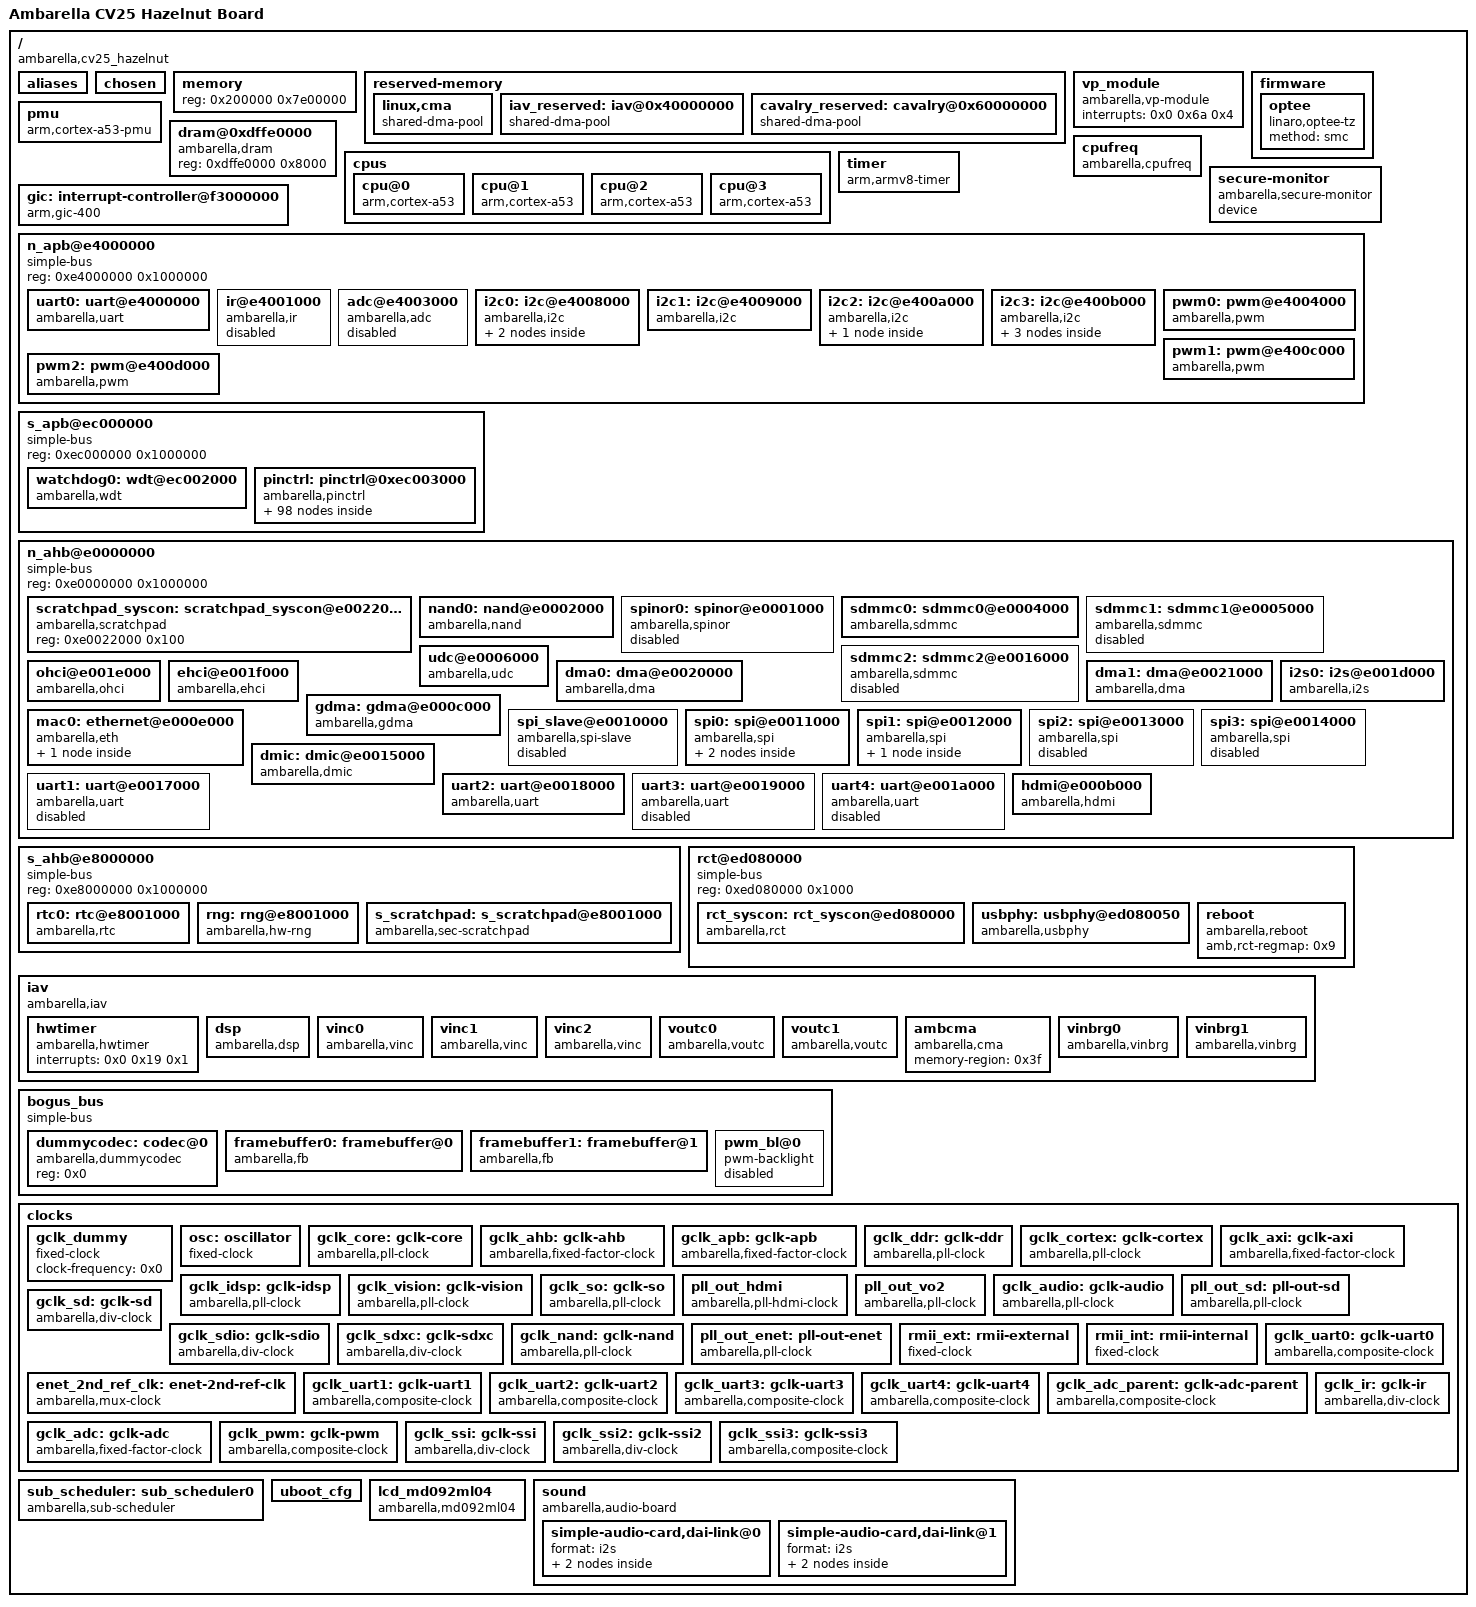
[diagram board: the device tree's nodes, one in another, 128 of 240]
/dts-v1/;

/ {
	compatible = "ambarella,cv25_hazelnut", "ambarella,cv25";
	interrupt-parent = <0x1>;
	#address-cells = <0x1>;
	#size-cells = <0x1>;
	model = "Ambarella CV25 Hazelnut Board";

	aliases {
		serial0 = "/n_apb@e4000000/uart@e4000000";
		serial1 = "/n_ahb@e0000000/uart@e0017000";
		serial2 = "/n_ahb@e0000000/uart@e0018000";
		serial3 = "/n_ahb@e0000000/uart@e0019000";
		serial4 = "/n_ahb@e0000000/uart@e001a000";
		nand = "/n_ahb@e0000000/nand@e0002000";
		sd0 = "/n_ahb@e0000000/sdmmc0@e0004000";
		sd1 = "/n_ahb@e0000000/sdmmc1@e0005000";
		sd2 = "/n_ahb@e0000000/sdmmc2@e0016000";
		spinor = "/n_ahb@e0000000/spinor@e0001000";
		i2c0 = "/n_apb@e4000000/i2c@e4008000";
		i2c1 = "/n_apb@e4000000/i2c@e4009000";
		i2c2 = "/n_apb@e4000000/i2c@e400a000";
		i2c3 = "/n_apb@e4000000/i2c@e400b000";
		spi0 = "/n_ahb@e0000000/spi@e0011000";
		spi1 = "/n_ahb@e0000000/spi@e0012000";
		spi2 = "/n_ahb@e0000000/spi@e0013000";
		spi3 = "/n_ahb@e0000000/spi@e0014000";
		ethernet0 = "/n_ahb@e0000000/ethernet@e000e000";
	};

	chosen {
		linux,stdout-path = "/n_apb@e4000000/uart@e4000000";
		stdout-path = "serial0";
		bootargs = "console=ttyS0 ubi.mtd=lnx root=ubi0:rootfs rw rootfstype=ubifs init=/linuxrc";
		ambarella,pm-gpio-notify-mcu = <0x6a>;
	};

	memory {
		device_type = "memory";
		reg = <0x200000 0x7e00000>;
	};

	reserved-memory {
		#address-cells = <0x1>;
		#size-cells = <0x1>;
		ranges;

		linux,cma {
			compatible = "shared-dma-pool";
			reusable;
			size = <0x3000000>;
			linux,cma-default;
		};

		iav_reserved: iav@0x40000000 {
			compatible = "shared-dma-pool";
			reusable;
			reg = <0x40000000 0x20000000>;
			linux,phandle = <0x3f>;
			phandle = <0x3f>;
		};

		cavalry_reserved: cavalry@0x60000000 {
			compatible = "shared-dma-pool";
			reusable;
			reg = <0x60000000 0x20000000>;
			linux,phandle = <0x4b>;
			phandle = <0x4b>;
		};
	};

	vp_module: vp_module {
		compatible = "ambarella,vp-module";
		interrupts = <0x0 0x6a 0x4>;
	};

	firmware {

		optee {
			compatible = "linaro,optee-tz";
			method = "smc";
		};
	};

	pmu {
		compatible = "arm,cortex-a53-pmu";
		interrupts = <0x0 0x4 0x4 0x0 0x5 0x4 0x0 0x6 0x4 0x0 0x7 0x4>;
	};

	dram@0xdffe0000 {
		compatible = "ambarella,dram";
		reg = <0xdffe0000 0x8000>;
	};

	cpus {
		#address-cells = <0x1>;
		#size-cells = <0x0>;

		cpu@0 {
			compatible = "arm,cortex-a53", "arm,armv8";
			device_type = "cpu";
			reg = <0x0>;
			enable-method = "spin-table";
		};

		cpu@1 {
			compatible = "arm,cortex-a53", "arm,armv8";
			device_type = "cpu";
			reg = <0x1>;
			enable-method = "spin-table";
		};

		cpu@2 {
			compatible = "arm,cortex-a53", "arm,armv8";
			device_type = "cpu";
			reg = <0x2>;
			enable-method = "spin-table";
		};

		cpu@3 {
			compatible = "arm,cortex-a53", "arm,armv8";
			device_type = "cpu";
			reg = <0x3>;
			enable-method = "spin-table";
		};
	};

	cpufreq {
		compatible = "ambarella,cpufreq";
		cpufreq-effective-clock = <0x0>;
		clocks = <0x2 0x3>;
		clock-names = "cortex_clk", "core_clk";
		clocks-frequency-cortex-core = <0x107ac0 0xa4100 0xc7380 0x7b0c0 0x927c0 0x52080>;
	};

	gic: interrupt-controller@f3000000 {
		compatible = "arm,gic-400";
		#interrupt-cells = <0x3>;
		#address-cells = <0x0>;
		interrupt-controller;
		reg = <0xf3001000 0x1000 0xf3002000 0x2000 0xf3004000 0x2000 0xf3006000 0x2000>;
		interrupts = <0x1 0x9 0xf04>;
		linux,phandle = <0x1>;
		phandle = <0x1>;
	};

	timer {
		compatible = "arm,armv8-timer";
		interrupts = <0x1 0xd 0xf08 0x1 0xe 0xf08 0x1 0xb 0xf08 0x1 0xa 0xf08>;
	};

	secure-monitor {
		compatible = "ambarella,secure-monitor";
		#address-cells = <0x1>;
		#size-cells = <0x0>;
		device;
	};

	n_apb@e4000000 {
		compatible = "simple-bus";
		#address-cells = <0x1>;
		#size-cells = <0x1>;
		reg = <0xe4000000 0x1000000>;
		ranges;

		uart0: uart@e4000000 {
			compatible = "ambarella,uart";
			reg = <0xe4000000 0x1000>;
			interrupts = <0x0 0x15 0x4>;
			pinctrl-names = "default";
			pinctrl-0 = <0x4>;
			clocks = <0x5>;
			status = "ok";
		};

		ir@e4001000 {
			compatible = "ambarella,ir";
			reg = <0xe4001000 0x1000>;
			interrupts = <0x0 0x14 0x4>;
			pinctrl-names = "default";
			pinctrl-0 = <0x6>;
			clocks = <0x7>;
			status = "disabled";
		};

		adc@e4003000 {
			compatible = "ambarella,adc";
			#io-channel-cells = <0x1>;
			reg = <0xe4003000 0x1000>;
			interrupts = <0x0 0xd 0x4>;
			clock-frequency = <0x2dc6c0>;
			clocks = <0x8>;
			amb,rct-regmap = <0x9>;
			amb,scaler-1v8 = <0x1>;
			status = "disabled";
		};

		i2c0: i2c@e4008000 {
			compatible = "ambarella,i2c";
			#address-cells = <0x1>;
			#size-cells = <0x0>;
			reg = <0xe4008000 0x1000>;
			interrupts = <0x0 0xf 0x4>;
			pinctrl-names = "default";
			pinctrl-0 = <0xa>;
			clocks = <0xb>;
			clock-frequency = <0x186a0>;
			amb,i2c-class = <0x81>;
			status = "ok";

			ak4951: codec@12 {
				compatible = "ambarella,ak4951";
				#sound-dai-cells = <0x0>;
				reg = <0x12>;
				gpios = <0xc 0xd 0x0>;
				pwr-gpios = <0xc 0xe 0x1>;
				linux,phandle = <0x4d>;
				phandle = <0x4d>;
			};

			ambvin0@01 {
				compatible = "ambarella,ambvin";
				reg = <0x1>;
			};
		};

		i2c1: i2c@e4009000 {
			compatible = "ambarella,i2c";
			#address-cells = <0x1>;
			#size-cells = <0x0>;
			reg = <0xe4009000 0x1000>;
			interrupts = <0x0 0x10 0x4>;
			pinctrl-names = "default";
			pinctrl-0 = <0xd>;
			clocks = <0xb>;
			clock-frequency = <0x186a0>;
			amb,i2c-class = <0x8>;
			status = "ok";
		};

		i2c2: i2c@e400a000 {
			compatible = "ambarella,i2c";
			#address-cells = <0x1>;
			#size-cells = <0x0>;
			reg = <0xe400a000 0x1000>;
			interrupts = <0x0 0x11 0x4>;
			clocks = <0xb>;
			pinctrl-names = "default";
			pinctrl-0 = <0xe>;
			clock-frequency = <0x186a0>;
			amb,i2c-class = <0x81>;
			status = "ok";

			it66121@4c {
				compatible = "it66121";
				reg = <0x4c>;
				rst_gpios = <0xc 0x3 0x0>;
			};
		};

		i2c3: i2c@e400b000 {
			compatible = "ambarella,i2c";
			#address-cells = <0x1>;
			#size-cells = <0x0>;
			reg = <0xe400b000 0x1000>;
			interrupts = <0x0 0x12 0x4>;
			clocks = <0xb>;
			pinctrl-names = "default";
			pinctrl-0 = <0xf>;
			clock-frequency = <0x186a0>;
			amb,i2c-class = <0x81>;
			status = "ok";

			pca9539: pca9539@74 {
				compatible = "nxp,pca9539";
				reg = <0x74>;
				gpio-controller;
				interrupt-parent = <0x10>;
				interrupt-controller;
				#gpio-cells = <0x2>;
				interrupts = <0x9 0x0>;
				linux,phandle = <0xc>;
				phandle = <0xc>;
			};

			isl12022: rtc@6f {
				compatible = "isil,isl12022";
				reg = <0x6f>;
			};

			ambvin1@01 {
				compatible = "ambarella,ambvin";
				reg = <0x1>;
			};
		};

		pwm0: pwm@e4004000 {
			compatible = "ambarella,pwm";
			reg = <0xe4004000 0x1000>;
			clock-frequency = <0x1e8480>;
			clocks = <0x11>;
			#pwm-cells = <0x3>;
			linux,phandle = <0x40>;
			phandle = <0x40>;
		};

		pwm1: pwm@e400c000 {
			compatible = "ambarella,pwm";
			reg = <0xe400c000 0x1000>;
			clock-frequency = <0x1e8480>;
			clocks = <0x11>;
			#pwm-cells = <0x3>;
		};

		pwm2: pwm@e400d000 {
			compatible = "ambarella,pwm";
			reg = <0xe400d000 0x1000>;
			clock-frequency = <0x989680>;
			clocks = <0x11>;
			#pwm-cells = <0x3>;
		};
	};

	s_apb@ec000000 {
		compatible = "simple-bus";
		#address-cells = <0x1>;
		#size-cells = <0x1>;
		reg = <0xec000000 0x1000000>;
		ranges;

		watchdog0: wdt@ec002000 {
			compatible = "ambarella,wdt";
			reg = <0xec002000 0x1000>;
			amb,rct-regmap = <0x9>;
			timeout-sec = <0xf>;
			amb,secure-ctrl-bit = <0x31>;
		};

		pinctrl: pinctrl@0xec003000 {
			compatible = "ambarella,pinctrl", "simple-bus";
			#address-cells = <0x1>;
			#size-cells = <0x0>;
			reg = <0xec003000 0x1000 0xec004000 0x1000 0xec005000 0x1000 0xec006000 0x1000 0xec000000 0x1000 0xe0022014 0x3c 0xed080314 0x13c>;
			reg-names = "gpio0", "gpio1", "gpio2", "gpio3", "iomux", "pad", "ds";
			#gpio-range-cells = <0x3>;
			linux,phandle = <0x12>;
			phandle = <0x12>;

			gpio: gpio@0 {
				compatible = "ambarella,gpio";
				reg = <0x0>;
				interrupts = <0x0 0x2b 0x4 0x0 0x2c 0x4 0x0 0x2d 0x4 0x0 0x2e 0x4>;
				gpio-controller;
				#gpio-cells = <0x2>;
				gpio-ranges = <0x12 0x0 0x0 0x6c>;
				interrupt-controller;
				#interrupt-cells = <0x2>;
				linux,phandle = <0x10>;
				phandle = <0x10>;
			};

			uart0_pins: uart0@0 {
				reg = <0x0>;
				amb,pinmux-ids = <0x1011 0x1012>;
				u-boot,dm-pre-reloc;
				linux,phandle = <0x4>;
				phandle = <0x4>;
			};

			uart1_pins: uart1@0 {
				reg = <0x0>;
				amb,pinmux-ids = <0x1057 0x1058>;
				linux,phandle = <0x31>;
				phandle = <0x31>;
			};

			uart1_flow_pins: uart1_flow@0 {
				reg = <0x0>;
				amb,pinmux-ids = <0x1059 0x105a>;
				linux,phandle = <0x32>;
				phandle = <0x32>;
			};

			uart2_pins: uart2@0 {
				reg = <0x0>;
				amb,pinmux-ids = <0x105b 0x105c>;
				linux,phandle = <0x34>;
				phandle = <0x34>;
			};

			uart2_flow_pins: uart2_flow@0 {
				reg = <0x0>;
				amb,pinmux-ids = <0x105d 0x105e>;
				linux,phandle = <0x35>;
				phandle = <0x35>;
			};

			uart3_pins_a: uart3@0 {
				reg = <0x0>;
				amb,pinmux-ids = <0x1048 0x1049>;
			};

			uart3_pins_b: uart3@1 {
				reg = <0x1>;
				amb,pinmux-ids = <0x4061 0x4062>;
				linux,phandle = <0x37>;
				phandle = <0x37>;
			};

			uart3_flow_pins_a: uart3_flow@0 {
				reg = <0x0>;
				amb,pinmux-ids = <0x104a 0x104b>;
			};

			uart3_flow_pins_b: uart3_flow@1 {
				reg = <0x1>;
				amb,pinmux-ids = <0x4063 0x4064>;
				linux,phandle = <0x38>;
				phandle = <0x38>;
			};

			uart4_pins_a: uart4@0 {
				reg = <0x0>;
				amb,pinmux-ids = <0x104c 0x104d>;
				linux,phandle = <0x3a>;
				phandle = <0x3a>;
			};

			uart4_pins_b: uart4@1 {
				reg = <0x1>;
				amb,pinmux-ids = <0x4065 0x4066>;
			};

			uart4_flow_pins_a: uart4_flow@0 {
				reg = <0x0>;
				amb,pinmux-ids = <0x104e 0x104f>;
				linux,phandle = <0x3b>;
				phandle = <0x3b>;
			};

			uart4_flow_pins_b: uart4_flow@1 {
				reg = <0x1>;
				amb,pinmux-ids = <0x4067 0x4068>;
			};

			nand0_pins: nand0@0 {
				reg = <0x0>;
				amb,pinmux-ids = <0x202d 0x202e 0x202f 0x2034 0x2035 0x2036 0x2037 0x2038 0x2039 0x203a 0x203b 0x203c 0x203d 0x203e 0x203f>;
				linux,phandle = <0x13>;
				phandle = <0x13>;
			};

			snand0_pins: snand0@0 {
				reg = <0x0>;
				amb,pinmux-ids = <0x402d 0x4037 0x403b 0x403c 0x403d 0x403e>;
				linux,phandle = <0x14>;
				phandle = <0x14>;
			};

			spinor0_pins: spinor0@0 {
				reg = <0x0>;
				amb,pinmux-ids = <0x302d 0x302f 0x3034 0x3035 0x3036 0x3037 0x3038 0x3039 0x303a 0x303b 0x303c 0x303d 0x303e>;
				linux,phandle = <0x16>;
				phandle = <0x16>;
			};

			sdmmc0_cd_pin: sdmmc0_cd@0 {
				reg = <0x0>;
				amb,pinmux-ids = <0x2032>;
				linux,phandle = <0x1a>;
				phandle = <0x1a>;
			};

			sdmmc0_wp_pin: sdmmc0_wp@0 {
				reg = <0x0>;
				amb,pinmux-ids = <0x2033>;
				linux,phandle = <0x1b>;
				phandle = <0x1b>;
			};

			sdmmc0_reset_pin: sdmmc0_reset@0 {
				reg = <0x0>;
				amb,pinmux-ids = <0x2051>;
			};

			sdmmc0_pins_1bit: sdmmc0@0 {
				reg = <0x0>;
				amb,pinmux-ids = <0x2030 0x2031 0x2040>;
			};

			sdmmc0_pins_4bit: sdmmc0@1 {
				reg = <0x1>;
				amb,pinmux-ids = <0x2030 0x2031 0x2040 0x2041 0x2042 0x2043>;
			};

			sdmmc0_pins_8bit: sdmmc0@2 {
				reg = <0x2>;
				amb,pinmux-ids = <0x2030 0x2031 0x2040 0x2041 0x2042 0x2043 0x2044 0x2045 0x2046 0x2047>;
				linux,phandle = <0x19>;
				phandle = <0x19>;
			};

			sdmmc1_cd_pin: sdmmc1_cd@0 {
				reg = <0x0>;
				amb,pinmux-ids = <0x204e>;
				linux,phandle = <0x1e>;
				phandle = <0x1e>;
			};

			sdmmc1_wp_pin: sdmmc1_wp@0 {
				reg = <0x0>;
				amb,pinmux-ids = <0x204f>;
				linux,phandle = <0x1f>;
				phandle = <0x1f>;
			};

			sdmmc1_reset_pin: sdmmc1_reset@0 {
				reg = <0x0>;
				amb,pinmux-ids = <0x2050>;
			};

			sdmmc1_pins_1bit: sdmmc1@0 {
				reg = <0x0>;
				amb,pinmux-ids = <0x2048 0x2049 0x204a>;
			};

			sdmmc1_pins_4bit: sdmmc1@1 {
				reg = <0x1>;
				amb,pinmux-ids = <0x2048 0x2049 0x204a 0x204b 0x204c 0x204d>;
				linux,phandle = <0x1d>;
				phandle = <0x1d>;
			};

			sdmmc2_cd_pin: sdmmc2_cd@0 {
				reg = <0x0>;
				amb,pinmux-ids = <0x1067>;
				linux,phandle = <0x22>;
				phandle = <0x22>;
			};

			sdmmc2_wp_pin: sdmmc2_wp@0 {
				reg = <0x0>;
				amb,pinmux-ids = <0x1068>;
			};

			sdmmc2_pins_1bit: sdmmc2@0 {
				reg = <0x0>;
				amb,pinmux-ids = <0x1065 0x1066 0x1061>;
			};

			sdmmc2_pins_4bit: sdmmc2@1 {
				reg = <0x1>;
				amb,pinmux-ids = <0x1065 0x1066 0x1061 0x1062 0x1063 0x1064>;
				linux,phandle = <0x21>;
				phandle = <0x21>;
			};

			rgmii_pins: eth0@0 {
				reg = <0x0>;
				amb,pinmux-ids = <0x401c 0x401d 0x401e 0x401f 0x4020 0x4021 0x4022 0x4023 0x4024 0x4025 0x4029 0x402a 0x402b 0x5026 0x5027>;
				linux,phandle = <0x28>;
				phandle = <0x28>;
			};

			rmii_pins: eth0@1 {
				reg = <0x1>;
				amb,pinmux-ids = <0x301c 0x301d 0x301e 0x3021 0x3022 0x3025 0x3029 0x302b 0x5026 0x5027>;
			};

			enet_ptp_pps_o_pins_a: enet_ptp_pps_o@0 {
				reg = <0x0>;
				amb,pinmux-ids = <0x4028>;
			};

			enet_ptp_pps_o_pins_b: enet_ptp_pps_o@1 {
				reg = <0x1>;
				amb,pinmux-ids = <0x3028>;
			};

			enet_2nd_ref_clk_pins_a: enet_2nd_ref_clk@0 {
				reg = <0x0>;
				amb,pinmux-ids = <0x302c>;
				linux,phandle = <0x29>;
				phandle = <0x29>;
			};

			enet_2nd_ref_clk_pins_b: enet_2nd_ref_clk@1 {
				reg = <0x1>;
				amb,pinmux-ids = <0x302a>;
			};

			i2c0_pins_a: i2c0@0 {
				reg = <0x0>;
				amb,pinmux-ids = <0x3001 0x3002>;
				linux,phandle = <0xa>;
				phandle = <0xa>;
			};

			i2c0_pins_b: i2c0@1 {
				reg = <0x1>;
				amb,pinmux-ids = <0x300f 0x3010>;
			};

			i2c0_pins_c: i2c0@2 {
				reg = <0x2>;
				amb,pinmux-ids = <0x304f 0x3050>;
			};

			i2c0_pins_d: i2c0@3 {
				reg = <0x3>;
				amb,pinmux-ids = <0x205f 0x2060>;
			};

			i2c1_pins_a: i2c1@0 {
				reg = <0x0>;
				amb,pinmux-ids = <0x2006 0x2007>;
			};

			i2c1_pins_b: i2c1@1 {
				reg = <0x1>;
				amb,pinmux-ids = <0x3065 0x3066>;
				linux,phandle = <0xd>;
				phandle = <0xd>;
			};

			i2c2_pins_a: i2c2@0 {
				reg = <0x0>;
				amb,pinmux-ids = <0x2004 0x2008>;
			};

			i2c2_pins_b: i2c2@1 {
				reg = <0x1>;
				amb,pinmux-ids = <0x3067 0x3068>;
				linux,phandle = <0xe>;
				phandle = <0xe>;
			};

			i2c3_pins: i2c3@0 {
				reg = <0x0>;
				amb,pinmux-ids = <0x200b 0x200c>;
				linux,phandle = <0xf>;
				phandle = <0xf>;
			};

			ir_pins: ir0@0 {
				reg = <0x0>;
				amb,pinmux-ids = <0x1003>;
				linux,phandle = <0x6>;
				phandle = <0x6>;
			};

			wdt_pins_a: wdt0@0 {
				reg = <0x0>;
				amb,pinmux-ids = <0x2003>;
			};

			wdt_pins_b: wdt0@1 {
				reg = <0x1>;
				amb,pinmux-ids = <0x3008>;
			};

			wdt_pins_c: wdt0@2 {
				reg = <0x2>;
				amb,pinmux-ids = <0x2015>;
			};

			wdt_pins_d: wdt0@3 {
				reg = <0x3>;
				amb,pinmux-ids = <0x202c>;
			};

			wdt_pins_e: wdt0@4 {
				reg = <0x4>;
				amb,pinmux-ids = <0x2054>;
			};

			wdt_pins_f: wdt0@5 {
				reg = <0x5>;
				amb,pinmux-ids = <0x5066>;
			};

			i2s0_pins: i2s0@0 {
				reg = <0x0>;
				amb,pinmux-ids = <0x1016 0x1017 0x1018 0x101b>;
				linux,phandle = <0x26>;
				phandle = <0x26>;
			};

			i2s0_ch2_pins: i2s0_ch2@0 {
				reg = <0x0>;
				amb,pinmux-ids = <0x1019 0x101a>;
			};

			dmic0_pins: dmic_pins@0 {
				reg = <0x0>;
				amb,pinmux-ids = <0x3014 0x3015>;
			};

			dmic1_pins: dmic_pins@1 {
				reg = <0x1>;
				amb,pinmux-ids = <0x3016 0x3017>;
			};

			dmic2_pins: dmic_pins@2 {
				reg = <0x2>;
				amb,pinmux-ids = <0x4019 0x401a>;
			};

			usb_host0_pins_a: uhc0@0 {
				reg = <0x0>;
				amb,pinmux-ids = <0x3019 0x301a>;
				linux,phandle = <0x3d>;
				phandle = <0x3d>;
			};

			usb_host0_pins_b: uhc0@1 {
				reg = <0x1>;
				amb,pinmux-ids = <0x4011 0x4012>;
			};

			usb_host0_pins_c: uhc0@2 {
				reg = <0x2>;
				amb,pinmux-ids = <0x3057 0x3059>;
			};

			usb_host0_pins_d: uhc0@3 {
				reg = <0x3>;
				amb,pinmux-ids = <0x5061 0x5062>;
			};

			pwm0_pins_a: pwm0@0 {
				reg = <0x0>;
				amb,pinmux-ids = <0x1013>;
			};

			pwm0_pins_b: pwm0@1 {
				reg = <0x1>;
				amb,pinmux-ids = <0x2020>;
			};

			pwm0_pins_c: pwm0@2 {
				reg = <0x2>;
				amb,pinmux-ids = <0x102c>;
				linux,phandle = <0x41>;
				phandle = <0x41>;
			};

			pwm1_pins: pwm1@0 {
				reg = <0x0>;
				amb,pinmux-ids = <0x1014>;
			};

			pwm2_pins: pwm2@0 {
				reg = <0x0>;
				amb,pinmux-ids = <0x1015>;
			};

			pwm3_pins_a: pwm3@0 {
				reg = <0x0>;
				amb,pinmux-ids = <0x3004>;
			};

			pwm3_pins_b: pwm3@1 {
				reg = <0x1>;
				amb,pinmux-ids = <0x2024>;
			};

			pwm4_pins_a: pwm4@0 {
				reg = <0x0>;
				amb,pinmux-ids = <0x3005>;
			};

			pwm4_pins_b: pwm4@1 {
				reg = <0x1>;
				amb,pinmux-ids = <0x2025>;
			};

			pwm5_pins_a: pwm5@0 {
				reg = <0x0>;
				amb,pinmux-ids = <0x3006>;
			};

			pwm5_pins_b: pwm5@1 {
				reg = <0x1>;
				amb,pinmux-ids = <0x2026>;
			};

			pwm6_pins_a: pwm6@0 {
				reg = <0x0>;
				amb,pinmux-ids = <0x3007>;
			};

			pwm6_pins_b: pwm6@1 {
				reg = <0x1>;
				amb,pinmux-ids = <0x2027>;
			};

			pwm7_pins_a: pwm7@0 {
				reg = <0x0>;
				amb,pinmux-ids = <0x3000>;
			};

			pwm7_pins_b: pwm7@1 {
				reg = <0x1>;
				amb,pinmux-ids = <0x2028>;
			};

			pwm7_pins_c: pwm7@2 {
				reg = <0x2>;
				amb,pinmux-ids = <0x5063>;
			};

			pwm8_pins_a: pwm8@0 {
				reg = <0x0>;
				amb,pinmux-ids = <0x201c>;
			};

			pwm8_pins_b: pwm8@1 {
				reg = <0x1>;
				amb,pinmux-ids = <0x2029>;
			};

			pwm8_pins_c: pwm8@2 {
				reg = <0x2>;
				amb,pinmux-ids = <0x5064>;
			};

			pwm9_pins_a: pwm9@0 {
				reg = <0x0>;
				amb,pinmux-ids = <0x201d>;
			};

			pwm9_pins_b: pwm9@1 {
				reg = <0x1>;
				amb,pinmux-ids = <0x202a>;
			};

			pwm9_pins_c: pwm9@2 {
				reg = <0x2>;
				amb,pinmux-ids = <0x5065>;
			};

			pwm10_pins: pwm10@0 {
				reg = <0x0>;
				amb,pinmux-ids = <0x201e>;
			};

			pwm11_pins: pwm11@0 {
				reg = <0x0>;
				amb,pinmux-ids = <0x201f>;
			};

			spi_slave_pins_a: spi_slave@0 {
				reg = <0x0>;
				amb,pinmux-ids = <0x200d 0x200e 0x200f 0x2010>;
				linux,phandle = <0x2b>;
				phandle = <0x2b>;
			};

			spi_slave_pins_b: spi_slave@1 {
				reg = <0x1>;
				amb,pinmux-ids = <0x3061 0x3062 0x3063 0x3064>;
			};

			spi0_pins_a: spi0@0 {
				reg = <0x0>;
				amb,pinmux-ids = <0x1004 0x1005 0x1006>;
				linux,phandle = <0x2c>;
				phandle = <0x2c>;
			};

			spi0_pins_b: spi0@1 {
				reg = <0x1>;
				amb,pinmux-ids = <0x2061 0x2062 0x2063>;
			};

			spi1_pins_a: spi1@0 {
				reg = <0x0>;
				amb,pinmux-ids = <0x2016 0x2017 0x2018>;
			};

			spi1_pins_b: spi1@1 {
				reg = <0x1>;
				amb,pinmux-ids = <0x3048 0x3049 0x304a>;
				linux,phandle = <0x2d>;
				phandle = <0x2d>;
			};

			spi1_pins_c: spi1@2 {
				reg = <0x2>;
				amb,pinmux-ids = <0x2057 0x2058 0x2059>;
			};

			spi1_pins_d: spi1@3 {
				reg = <0x3>;
				amb,pinmux-ids = <0x2065 0x2066 0x2067>;
			};

			spi2_pins: spi2@0 {
				reg = <0x0>;
				amb,pinmux-ids = <0x1009 0x100a 0x100b>;
				linux,phandle = <0x2e>;
				phandle = <0x2e>;
			};

			spi3_pins: spi3@0 {
				reg = <0x0>;
				amb,pinmux-ids = <0x100d 0x100e 0x100f>;
				linux,phandle = <0x30>;
				phandle = <0x30>;
			};

			vout0_pins: vout0@0 {
				reg = <0x0>;
				amb,pinmux-ids = <0x101c 0x101d 0x101e 0x101f 0x1020 0x1021 0x1022 0x1023 0x1024 0x1025 0x1026 0x1027 0x1028 0x1029 0x102a 0x102b 0x305b 0x305c 0x305d 0x305e>;
				amb,pinconf-ids = <0xba001c 0xba001d 0xba001e 0xba001f 0xba0020 0xba0021 0xba0022 0xba0023 0xba0024 0xba0025 0xba0026 0xba0027 0xba0028 0xba0029 0xba002a 0xba002b 0xba005b 0xba005c 0xba005d 0xba005e>;
			};
		};
	};

	n_ahb@e0000000 {
		compatible = "simple-bus";
		#address-cells = <0x1>;
		#size-cells = <0x1>;
		reg = <0xe0000000 0x1000000>;
		ranges;

		scratchpad_syscon: scratchpad_syscon@e0022000 {
			compatible = "ambarella,scratchpad", "syscon";
			reg = <0xe0022000 0x100>;
			linux,phandle = <0x24>;
			phandle = <0x24>;
		};

		nand0: nand@e0002000 {
			compatible = "ambarella,nand";
			#address-cells = <0x1>;
			#size-cells = <0x1>;
			reg = <0xe0002000 0x1000>;
			interrupts = <0x0 0x44 0x4>;
			amb,rct-regmap = <0x9>;
			pinctrl-names = "default", "spinand";
			pinctrl-0 = <0x13>;
			pinctrl-1 = <0x14>;
			clocks = <0x15>;
			nand-on-flash-bbt;
		};

		spinor0: spinor@e0001000 {
			compatible = "ambarella,spinor";
			reg = <0xe0001000 0x2ff>;
			interrupts = <0x0 0x49 0x4>;
			pinctrl-names = "default";
			pinctrl-0 = <0x16>;
			clocks = <0x17>;
			dmas = <0x18 0x5 0x18 0x6>;
			dma-names = "tx", "rx";
			max-frequency = <0x2faf080>;
			status = "disabled";
		};

		sdmmc0: sdmmc0@e0004000 {
			compatible = "ambarella,sdmmc";
			#address-cells = <0x1>;
			#size-cells = <0x0>;
			reg = <0xe0004000 0x1000>;
			interrupts = <0x0 0x48 0x4>;
			pinctrl-names = "default";
			pinctrl-0 = <0x19 0x1a 0x1b>;
			clocks = <0x1c>;
			amb,rct-regmap = <0x9 0x4c0 0x4c4 0x664 0x4f0 0x0>;
			amb,tuning-tx-clk = <0x0>;
			max-frequency = <0x7270e00>;
			bus-width = <0x8>;
			cap-sdio-irq;
			cap-sd-highspeed;
			cap-mmc-highspeed;
			mmc-hs200-1_8v;
			pwr-gpios = <0x10 0x51 0x1>;
			v18-gpios = <0x10 0x69 0x1>;
		};

		sdmmc1: sdmmc1@e0005000 {
			compatible = "ambarella,sdmmc";
			#address-cells = <0x1>;
			#size-cells = <0x0>;
			reg = <0xe0005000 0x1000>;
			interrupts = <0x0 0x47 0x4>;
			pinctrl-names = "default";
			pinctrl-0 = <0x1d 0x1e 0x1f>;
			clocks = <0x20>;
			amb,rct-regmap = <0x9 0x4c8 0x4cc 0x668 0x4f0 0x10>;
			amb,tuning-tx-clk = <0x0>;
			max-frequency = <0x7270e00>;
			bus-width = <0x4>;
			cap-sdio-irq;
			cap-sd-highspeed;
			cap-mmc-highspeed;
			pwr-gpios = <0x10 0x50 0x1>;
			status = "disabled";
		};

		sdmmc2: sdmmc2@e0016000 {
			compatible = "ambarella,sdmmc";
			#address-cells = <0x1>;
			#size-cells = <0x0>;
			reg = <0xe0016000 0x1000>;
			interrupts = <0x0 0x40 0x4>;
			pinctrl-names = "default";
			pinctrl-0 = <0x21 0x22>;
			clocks = <0x23>;
			max-frequency = <0x5b8d800>;
			bus-width = <0x4>;
			cap-sdio-irq;
			cap-sd-highspeed;
			cap-mmc-highspeed;
			pwr-gpios = <0x10 0x68 0x1>;
			status = "disabled";
		};

		udc@e0006000 {
			compatible = "ambarella,udc";
			reg = <0xe0006000 0x2000>;
			interrupts = <0x0 0x43 0x4>;
			amb,rct-regmap = <0x9>;
			amb,scr-regmap = <0x24>;
			amb,usbphy = <0x25>;
		};

		ohci@e001e000 {
			compatible = "ambarella,ohci";
			reg = <0xe001e000 0x1000>;
			interrupts = <0x0 0x42 0x4>;
			amb,usbphy = <0x25>;
		};

		ehci@e001f000 {
			compatible = "ambarella,ehci";
			reg = <0xe001f000 0x1000>;
			interrupts = <0x0 0x41 0x4>;
			amb,usbphy = <0x25>;
		};

		dma0: dma@e0020000 {
			compatible = "ambarella,dma";
			reg = <0xe0020000 0x1000 0xe0022050 0x8>;
			interrupts = <0x0 0x53 0x4>;
			#dma-cells = <0x1>;
			dma-channels = <0x8>;
			dma-requests = <0x17>;
			linux,phandle = <0x18>;
			phandle = <0x18>;
		};

		dma1: dma@e0021000 {
			compatible = "ambarella,dma";
			reg = <0xe0021000 0x1000 0xe0022058 0x8>;
			interrupts = <0x0 0x54 0x4>;
			#dma-cells = <0x1>;
			dma-channels = <0x8>;
			dma-requests = <0x17>;
			linux,phandle = <0x2f>;
			phandle = <0x2f>;
		};

		gdma: gdma@e000c000 {
			compatible = "ambarella,gdma";
			reg = <0xe000c000 0x400>;
			interrupts = <0x0 0x46 0x1>;
		};

		i2s0: i2s@e001d000 {
			compatible = "ambarella,i2s";
			#sound-dai-cells = <0x0>;
			reg = <0xe001d000 0x1000>;
			pinctrl-names = "default";
			pinctrl-0 = <0x26>;
			clocks = <0x27>;
			amb,i2s-channels = <0x2>;
			amb,default-mclk = <0xbb8000>;
			dmas = <0x18 0x15 0x18 0x16>;
			dma-names = "tx", "rx";
			linux,phandle = <0x4c>;
			phandle = <0x4c>;
		};

		mac0: ethernet@e000e000 {
			compatible = "ambarella,eth";
			#address-cells = <0x1>;
			#size-cells = <0x0>;
			reg = <0xe000e000 0x2000>;
			interrupts = <0x0 0x3a 0x4>;
			pinctrl-names = "default";
			pinctrl-0 = <0x28 0x29>;
			phy-mode = "rgmii";
			amb,rct-regmap = <0x9>;
			amb,scr-regmap = <0x24>;
			amb,tx-ring-size = <0x20>;
			amb,rx-ring-size = <0x40>;
			amb,ipc-tx;
			amb,ipc-rx;
			amb,enhance;
			amb,ahb-12mhz-div = <0x5>;
			clock-names = "ptp_ref";
			clocks = <0x2a>;
			amb,ext-ref-clk;
			amb,tx-clk-invert;

			phy@0 {
				reg = <0x0>;
				rst-gpios = <0xc 0xb 0x0>;
			};
		};

		spi_slave@e0010000 {
			compatible = "ambarella,spi-slave";
			reg = <0xe0010000 0x1000>;
			interrupts = <0x0 0x50 0x4>;
			pinctrl-names = "default";
			pinctrl-0 = <0x2b>;
			status = "disabled";
		};

		spi0: spi@e0011000 {
			compatible = "ambarella,spi";
			#address-cells = <0x1>;
			#size-cells = <0x0>;
			reg = <0xe0011000 0x1000>;
			interrupts = <0x0 0x4a 0x4>;
			pinctrl-names = "default";
			pinctrl-0 = <0x2c>;
			amb,clk-freq = <0x337f980>;
			dmas = <0x18 0x1 0x18 0x2>;
			dma-names = "tx", "rx";
			status = "ok";
			cs-gpios = <0x10 0x7 0x0 0x10 0x8 0x0>;

			ambvin0@0 {
				compatible = "ambarella,ambvin";
				reg = <0x0>;
				spi-max-frequency = <0xf4240>;
				spi-cpha;
				spi-cpol;
			};

			ambvin1@0 {
				compatible = "ambarella,ambvin";
				reg = <0x1>;
				spi-max-frequency = <0xf4240>;
				spi-cpha;
				spi-cpol;
			};
		};

		spi1: spi@e0012000 {
			compatible = "ambarella,spi";
			#address-cells = <0x1>;
			#size-cells = <0x0>;
			reg = <0xe0012000 0x1000>;
			interrupts = <0x0 0x4b 0x4>;
			pinctrl-names = "default";
			pinctrl-0 = <0x2d>;
			amb,clk-freq = <0x337f980>;
			dmas = <0x18 0x3 0x18 0x4>;
			dma-names = "tx", "rx";
			status = "ok";
			cs-gpios = <0x10 0x4e 0x0>;

			gyro@0 {
				compatible = "ambarella,gyro";
				reg = <0x0>;
				spi-max-frequency = <0x1312d00>;
				spi-cpha;
				spi-cpol;
				x_axis = <0x1>;
				y_axis = <0x3>;
				z_axis = <0x5>;
				irq-gpio = <0x10 0x8 0x0>;
			};
		};

		spi2: spi@e0013000 {
			compatible = "ambarella,spi";
			#address-cells = <0x1>;
			#size-cells = <0x0>;
			reg = <0xe0013000 0x1000>;
			interrupts = <0x0 0x4c 0x4>;
			pinctrl-names = "default";
			pinctrl-0 = <0x2e>;
			amb,clk-freq = <0x337f980>;
			dmas = <0x2f 0x11 0x2f 0x12>;
			dma-names = "tx", "rx";
			status = "disabled";
		};

		spi3: spi@e0014000 {
			compatible = "ambarella,spi";
			#address-cells = <0x1>;
			#size-cells = <0x0>;
			reg = <0xe0014000 0x1000>;
			interrupts = <0x0 0x4d 0x4>;
			pinctrl-names = "default";
			pinctrl-0 = <0x30>;
			amb,clk-freq = <0x337f980>;
			dmas = <0x2f 0x13 0x2f 0x14>;
			dma-names = "tx", "rx";
			status = "disabled";
		};

		dmic: dmic@e0015000 {
			compatible = "ambarella,dmic";
			reg = <0xe0015000 0x1000>;
			amb,scr-regmap = <0x24>;
			#sound-dai-cells = <0x0>;
			amb,custom-iir;
		};

		uart1: uart@e0017000 {
			compatible = "ambarella,uart";
			reg = <0xe0017000 0x1000>;
			interrupts = <0x0 0x3b 0x4>;
			pinctrl-names = "default";
			pinctrl-0 = <0x31 0x32>;
			clocks = <0x33>;
			status = "disabled";
			amb,msr-used;
			amb,txdma-used;
			amb,rxdma-used;
			dmas = <0x18 0x9 0x18 0xa>;
			dma-names = "tx", "rx";
		};

		uart2: uart@e0018000 {
			compatible = "ambarella,uart";
			reg = <0xe0018000 0x1000>;
			interrupts = <0x0 0x3c 0x4>;
			pinctrl-names = "default";
			pinctrl-0 = <0x34 0x35>;
			clocks = <0x36>;
			dmas = <0x2f 0xb 0x2f 0xc>;
			dma-names = "tx", "rx";
			status = "ok";
		};

		uart3: uart@e0019000 {
			compatible = "ambarella,uart";
			reg = <0xe0019000 0x1000>;
			interrupts = <0x0 0x3d 0x4>;
			pinctrl-names = "default";
			pinctrl-0 = <0x37 0x38>;
			clocks = <0x39>;
			amb,msr-used;
			amb,txdma-used;
			amb,rxdma-used;
			dmas = <0x2f 0xd 0x2f 0xe>;
			dma-names = "tx", "rx";
			status = "disabled";
		};

		uart4: uart@e001a000 {
			compatible = "ambarella,uart";
			reg = <0xe001a000 0x1000>;
			interrupts = <0x0 0x3e 0x4>;
			pinctrl-names = "default";
			pinctrl-0 = <0x3a 0x3b>;
			clocks = <0x3c>;
			amb,msr-used;
			amb,txdma-used;
			amb,rxdma-used;
			dmas = <0x2f 0xf 0x2f 0x10>;
			dma-names = "tx", "rx";
			status = "disabled";
		};

		hdmi@e000b000 {
			compatible = "ambarella,hdmi";
			reg = <0xe000b000 0x1000>;
			interrupts = <0x0 0x55 0x4>;
			interrupt-names = "hdmi";
			amb,hdmiphy = <0xed080010>;
			amb,hdmi-version = <0x14>;
			amb,i2c-adapter = <0x1>;
		};
	};

	s_ahb@e8000000 {
		compatible = "simple-bus";
		#address-cells = <0x1>;
		#size-cells = <0x1>;
		reg = <0xe8000000 0x1000000>;
		ranges;

		rtc0: rtc@e8001000 {
			compatible = "ambarella,rtc";
			reg = <0xe8001000 0x1000>;
			amb,secure-ctrl-bit = <0x1f>;
		};

		rng: rng@e8001000 {
			compatible = "ambarella,hw-rng";
			reg = <0xe8001000 0x14>;
			amb,rct-regmap = <0x9>;
			amb,secure-ctrl-bit = <0x1f>;
		};

		s_scratchpad: s_scratchpad@e8001000 {
			compatible = "ambarella,sec-scratchpad";
			reg = <0xe8001000 0x1000>;
			amb,secure-ctrl-bit = <0x1f>;
		};
	};

	rct@ed080000 {
		compatible = "simple-bus";
		#address-cells = <0x1>;
		#size-cells = <0x1>;
		reg = <0xed080000 0x1000>;
		ranges;

		rct_syscon: rct_syscon@ed080000 {
			compatible = "ambarella,rct", "syscon";
			reg = <0xed080000 0x1000>;
			amb,secure-ctrl-bit = <0x44>;
			linux,phandle = <0x9>;
			phandle = <0x9>;
		};

		usbphy: usbphy@ed080050 {
			compatible = "ambarella,usbphy";
			reg = <0xed080050 0x4 0xe0022060 0x4 0xed0802c0 0x4>;
			amb,host-phy-num = <0x1>;
			amb,ocp-polarity = <0x0>;
			pinctrl-names = "default";
			pinctrl-0 = <0x3d>;
			hub-gpios = <0xc 0xa 0x0>;
			linux,phandle = <0x25>;
			phandle = <0x25>;
		};

		reboot {
			compatible = "ambarella,reboot";
			amb,rct-regmap = <0x9>;
		};
	};

	iav {
		compatible = "ambarella,iav";
		#address-cells = <0x1>;
		#size-cells = <0x1>;

		hwtimer {
			compatible = "ambarella,hwtimer";
			interrupts = <0x0 0x19 0x1>;
			interrupt-names = "hwtimer";
		};

		dsp {
			compatible = "ambarella,dsp";
			interrupts = <0x0 0x8d 0x1 0x0 0x8e 0x1 0x0 0x8f 0x1 0x0 0x90 0x1>;
			interrupt-names = "vdsp", "vapi", "venc", "vcap";
		};

		vinc0 {
			compatible = "ambarella,vinc";
			interrupts = <0x0 0x6e 0x1 0x0 0x6f 0x1 0x0 0x70 0x1>;
			interrupt-names = "idsp", "idsp_sof", "idsp_last_pixel";
			clocks = <0x3e>;
			vinrst-gpios = <0x10 0x54 0x0>;
		};

		vinc1 {
			compatible = "ambarella,vinc";
			interrupts = <0x0 0x87 0x1 0x0 0x88 0x1 0x0 0x89 0x1>;
			interrupt-names = "idsp", "idsp_sof", "idsp_last_pixel";
			clocks = <0x3e>;
			vinrst-gpios = <0x10 0x13 0x0>;
		};

		vinc2 {
			compatible = "ambarella,vinc";
			interrupts = <0x0 0x72 0x1 0x0 0x73 0x1 0x0 0x74 0x1>;
			interrupt-names = "idsp", "idsp_sof", "idsp_last_pixel";
			clocks = <0x3e>;
		};

		voutc0 {
			compatible = "ambarella,voutc";
			output-type = "digital", "mipi_dsi", "fpd_link";
			interrupts = <0x0 0x59 0x1>;
			interrupt-names = "vout0";
			rct-regmap = <0x9>;
			pinctrl-names;
			pinctrl-0;
		};

		voutc1 {
			compatible = "ambarella,voutc";
			output-type = "hdmi", "mipi_csi", "cvbs";
			interrupts = <0x0 0x58 0x1>;
			interrupt-names = "vout1";
			rct-regmap = <0x9>;
		};

		ambcma {
			compatible = "ambarella,cma";
			memory-region = <0x3f>;
		};

		vinbrg0 {
			compatible = "ambarella,vinbrg";
			brgpwr-gpios = <0x10 0x6 0x1>;
			brgrst-gpios = <0x10 0x4 0x0 0xc 0x1 0x0>;
			bus-addr = <0x0>;
		};

		vinbrg1 {
			compatible = "ambarella,vinbrg";
			brgpwr-gpios = <0x10 0x6 0x1>;
			brgrst-gpios = <0x10 0x5 0x0 0xc 0x0 0x0>;
			bus-addr = <0x1>;
		};
	};

	bogus_bus {
		compatible = "simple-bus";
		#address-cells = <0x1>;
		#size-cells = <0x0>;

		dummycodec: codec@0 {
			compatible = "ambarella,dummycodec";
			reg = <0x0>;
			#sound-dai-cells = <0x0>;
			linux,phandle = <0x4e>;
			phandle = <0x4e>;
		};

		framebuffer0: framebuffer@0 {
			compatible = "ambarella,fb";
			reg = <0x0>;
			amb,vout-id = <0x0>;
			amb,format = "rgb565";
		};

		framebuffer1: framebuffer@1 {
			compatible = "ambarella,fb";
			reg = <0x1>;
			amb,vout-id = <0x1>;
			amb,format = "rgb565";
		};

		pwm_bl@0 {
			compatible = "pwm-backlight";
			reg = <0x0>;
			pwms = <0x40 0x0 0x9c40 0x0>;
			pinctrl-names = "default";
			pinctrl-0 = <0x41>;
			brightness-levels = <0x0 0x4 0x8 0x10 0x20 0x40 0x80 0xff>;
			default-brightness-level = <0x7>;
			status = "disabled";
		};
	};

	clocks {
		#address-cells = <0x1>;
		#size-cells = <0x1>;
		ranges;

		gclk_dummy: gclk_dummy {
			#clock-cells = <0x0>;
			compatible = "fixed-clock";
			clock-frequency = <0x0>;
		};

		osc: oscillator {
			compatible = "fixed-clock";
			#clock-cells = <0x0>;
			clock-frequency = <0x16e3600>;
			clock-output-names = "osc";
			linux,phandle = <0x2a>;
			phandle = <0x2a>;
		};

		gclk_core: gclk-core {
			#clock-cells = <0x0>;
			compatible = "ambarella,pll-clock";
			reg = <0xed080000 0x4 0xed080004 0x4 0xed080100 0x4 0xed080104 0x4 0x0 0x0 0x0 0x0>;
			clocks = <0x2a>;
			clock-output-names = "gclk_core";
			linux,phandle = <0x3>;
			phandle = <0x3>;
		};

		gclk_ahb: gclk-ahb {
			#clock-cells = <0x0>;
			compatible = "ambarella,fixed-factor-clock";
			clocks = <0x3>;
			clock-output-names = "gclk_ahb";
			clock-mult = <0x1>;
			clock-div = <0x2>;
		};

		gclk_apb: gclk-apb {
			#clock-cells = <0x0>;
			compatible = "ambarella,fixed-factor-clock";
			clocks = <0x3>;
			clock-output-names = "gclk_apb";
			clock-mult = <0x1>;
			clock-div = <0x4>;
			linux,phandle = <0xb>;
			phandle = <0xb>;
		};

		gclk_ddr: gclk-ddr {
			#clock-cells = <0x0>;
			compatible = "ambarella,pll-clock";
			reg = <0xed0800dc 0x4 0xed0800e0 0x4 0xed080110 0x4 0xed080114 0x4 0x0 0x0 0x0 0x0>;
			clocks = <0x2a>;
			clock-output-names = "gclk_ddr";
			amb,fix-divider = <0x2>;
		};

		gclk_cortex: gclk-cortex {
			#clock-cells = <0x0>;
			compatible = "ambarella,pll-clock";
			reg = <0xed080264 0x4 0xed080268 0x4 0xed08026c 0x4 0xed080270 0x4 0x0 0x0 0x0 0x0>;
			clocks = <0x2a>;
			clock-output-names = "gclk_cortex";
			linux,phandle = <0x2>;
			phandle = <0x2>;
		};

		gclk_axi: gclk-axi {
			#clock-cells = <0x0>;
			compatible = "ambarella,fixed-factor-clock";
			clocks = <0x2>;
			clock-output-names = "gclk_axi";
			clock-mult = <0x1>;
			clock-div = <0x3>;
		};

		gclk_idsp: gclk-idsp {
			#clock-cells = <0x0>;
			compatible = "ambarella,pll-clock";
			reg = <0xed0800e4 0x4 0xed0800e8 0x4 0xed080108 0x4 0xed08010c 0x4 0x0 0x0 0xed0801f4 0x4>;
			clocks = <0x2a>;
			clock-output-names = "gclk_idsp";
			amb,extra-post-scaler;
		};

		gclk_vision: gclk-vision {
			#clock-cells = <0x0>;
			compatible = "ambarella,pll-clock";
			reg = <0xed0806e4 0x4 0xed0806e8 0x4 0xed0806ec 0x4 0xed0806f0 0x4 0x0 0x0 0x0 0x0>;
			clocks = <0x2a>;
			clock-output-names = "gclk_vision";
			linux,phandle = <0x48>;
			phandle = <0x48>;
		};

		gclk_so: gclk-so {
			#clock-cells = <0x0>;
			compatible = "ambarella,pll-clock";
			reg = <0xed080024 0x4 0xed080028 0x4 0xed08011c 0x4 0xed080120 0x4 0xed08004c 0x4 0xed080030 0x4>;
			clocks = <0x2a>;
			clock-output-names = "gclk_so";
			assigned-clocks = <0x3e>;
			assigned-clock-rates = <0x2367b88>;
			amb,extra-pre-scaler;
			amb,extra-post-scaler;
			amb,frac-mode;
			linux,phandle = <0x3e>;
			phandle = <0x3e>;
		};

		pll_out_hdmi: pll_out_hdmi {
			#clock-cells = <0x0>;
			compatible = "ambarella,pll-hdmi-clock";
			reg = <0xed080164 0x4 0xed080168 0x4 0xed080150 0x4 0xed080154 0x4 0xed080170 0x4 0x0 0x0>;
			clocks = <0x2a>;
			clock-output-names = "pll_out_hdmi";
			assigned-clocks = <0x42>;
			assigned-clock-rates = <0x1017df80>;
			amb,extra-pre-scaler;
			amb,frac-mode;
			amb,ctrl2-val = <0x30520000>;
			amb,ctrl3-val = <0x88004>;
			amb,min-vco = <0x9c4>;
			linux,phandle = <0x42>;
			phandle = <0x42>;
		};

		pll_out_vo2: pll_out_vo2 {
			#clock-cells = <0x0>;
			compatible = "ambarella,pll-clock";
			reg = <0xed0800c0 0x4 0xed0800c4 0x4 0xed08013c 0x4 0xed080140 0x4 0xed0800c8 0x4 0x0 0x0>;
			clocks = <0x2a>;
			clock-output-names = "pll_out_vo2";
			assigned-clocks = <0x43>;
			assigned-clock-rates = <0x16e3600>;
			amb,extra-pre-scaler;
			amb,frac-mode;
			linux,phandle = <0x43>;
			phandle = <0x43>;
		};

		gclk_audio: gclk-audio {
			#clock-cells = <0x0>;
			compatible = "ambarella,pll-clock";
			reg = <0xed080054 0x4 0xed080058 0x4 0xed080124 0x4 0xed08012c 0x4 0xed080060 0x4 0xed08005c 0x4>;
			clocks = <0x2a>;
			clock-output-names = "gclk_audio";
			assigned-clocks = <0x27>;
			assigned-clock-rates = <0xbb8000>;
			amb,extra-pre-scaler;
			amb,extra-post-scaler;
			amb,frac-mode;
			linux,phandle = <0x27>;
			phandle = <0x27>;
		};

		pll_out_sd: pll-out-sd {
			#clock-cells = <0x0>;
			compatible = "ambarella,pll-clock";
			reg = <0xed0804ac 0x4 0xed0804b0 0x4 0xed0804b4 0x4 0xed0804b8 0x4 0x0 0x0 0x0 0x0>;
			clocks = <0x2a>;
			clock-output-names = "pll_out_sd";
			linux,phandle = <0x44>;
			phandle = <0x44>;
		};

		gclk_sd: gclk-sd {
			#clock-cells = <0x0>;
			compatible = "ambarella,div-clock";
			reg = <0xed08000c 0x4>;
			clocks = <0x44>;
			clock-output-names = "gclk_sd";
			amb,div-width = <0x10>;
			amb,div-shift = <0x0>;
			linux,phandle = <0x1c>;
			phandle = <0x1c>;
		};

		gclk_sdio: gclk-sdio {
			#clock-cells = <0x0>;
			compatible = "ambarella,div-clock";
			reg = <0xed080434 0x4>;
			clocks = <0x44>;
			clock-output-names = "gclk_sdio";
			amb,div-width = <0x10>;
			amb,div-shift = <0x0>;
			linux,phandle = <0x23>;
			phandle = <0x23>;
		};

		gclk_sdxc: gclk-sdxc {
			#clock-cells = <0x0>;
			compatible = "ambarella,div-clock";
			reg = <0xed080430 0x4>;
			clocks = <0x44>;
			clock-output-names = "gclk_sdxc";
			amb,div-width = <0x10>;
			amb,div-shift = <0x0>;
			linux,phandle = <0x20>;
			phandle = <0x20>;
		};

		gclk_nand: gclk-nand {
			#clock-cells = <0x0>;
			compatible = "ambarella,pll-clock";
			reg = <0xed0806f8 0x4 0xed0806fc 0x4 0xed080700 0x4 0xed080704 0x4 0x0 0x0 0x0 0x0>;
			clocks = <0x2a>;
			clock-output-names = "gclk_nand";
			linux,phandle = <0x15>;
			phandle = <0x15>;
		};

		pll_out_enet: pll-out-enet {
			#clock-cells = <0x0>;
			compatible = "ambarella,pll-clock";
			reg = <0xed080520 0x4 0xed080524 0x4 0xed080528 0x4 0xed08052c 0x4 0x0 0x0 0x0 0x0>;
			clocks = <0x2a>;
			clock-output-names = "pll_out_enet";
			linux,phandle = <0x47>;
			phandle = <0x47>;
		};

		rmii_ext: rmii-external {
			compatible = "fixed-clock";
			#clock-cells = <0x0>;
			clock-frequency = <0x17d7840>;
			clock-output-names = "rmii_ext";
			linux,phandle = <0x45>;
			phandle = <0x45>;
		};

		rmii_int: rmii-internal {
			compatible = "fixed-clock";
			#clock-cells = <0x0>;
			clock-frequency = <0x2faf080>;
			clock-output-names = "rmii_int";
			linux,phandle = <0x46>;
			phandle = <0x46>;
		};

		enet_2nd_ref_clk: enet-2nd-ref-clk {
			#clock-cells = <0x0>;
			compatible = "ambarella,mux-clock";
			reg = <0xed0806b8 0x4>;
			clocks = <0x45 0x46>;
			clock-output-names = "enet_2nd_ref_clk";
		};

		gclk_uart0: gclk-uart0 {
			#clock-cells = <0x0>;
			compatible = "ambarella,composite-clock";
			reg = <0xed080038 0x4 0xed0801c8 0x4>;
			clocks = <0x2a 0x3 0x47 0x44>;
			clock-output-names = "gclk_uart0";
			assigned-clocks = <0x5>;
			assigned-clock-parents = <0x2a>;
			assigned-clock-rates = <0x16e3600>;
			amb,div-width = <0x18>;
			amb,div-shift = <0x0>;
			linux,phandle = <0x5>;
			phandle = <0x5>;
		};

		gclk_uart1: gclk-uart1 {
			#clock-cells = <0x0>;
			compatible = "ambarella,composite-clock";
			reg = <0xed080714 0x4 0xed08072c 0x4>;
			clocks = <0x2a 0x3 0x47 0x44>;
			clock-output-names = "gclk_uart1";
			assigned-clocks = <0x33>;
			assigned-clock-parents = <0x2a>;
			assigned-clock-rates = <0x16e3600>;
			amb,div-width = <0x18>;
			amb,div-shift = <0x0>;
			linux,phandle = <0x33>;
			phandle = <0x33>;
		};

		gclk_uart2: gclk-uart2 {
			#clock-cells = <0x0>;
			compatible = "ambarella,composite-clock";
			reg = <0xed080718 0x4 0xed080730 0x4>;
			clocks = <0x2a 0x3 0x47 0x44>;
			clock-output-names = "gclk_uart2";
			assigned-clocks = <0x36>;
			assigned-clock-parents = <0x2a>;
			assigned-clock-rates = <0x16e3600>;
			amb,div-width = <0x18>;
			amb,div-shift = <0x0>;
			linux,phandle = <0x36>;
			phandle = <0x36>;
		};

		gclk_uart3: gclk-uart3 {
			#clock-cells = <0x0>;
			compatible = "ambarella,composite-clock";
			reg = <0xed08071c 0x4 0xed080734 0x4>;
			clocks = <0x2a 0x3 0x47 0x44>;
			clock-output-names = "gclk_uart3";
			assigned-clocks = <0x39>;
			assigned-clock-parents = <0x2a>;
			assigned-clock-rates = <0x16e3600>;
			amb,div-width = <0x18>;
			amb,div-shift = <0x0>;
			linux,phandle = <0x39>;
			phandle = <0x39>;
		};

		gclk_uart4: gclk-uart4 {
			#clock-cells = <0x0>;
			compatible = "ambarella,composite-clock";
			reg = <0xed080720 0x4 0xed080738 0x4>;
			clocks = <0x2a 0x3 0x47 0x44>;
			clock-output-names = "gclk_uart4";
			assigned-clocks = <0x3c>;
			assigned-clock-parents = <0x2a>;
			assigned-clock-rates = <0x16e3600>;
			amb,div-width = <0x18>;
			amb,div-shift = <0x0>;
			linux,phandle = <0x3c>;
			phandle = <0x3c>;
		};

		gclk_adc_parent: gclk-adc-parent {
			#clock-cells = <0x0>;
			compatible = "ambarella,composite-clock";
			reg = <0xed08009c 0x4 0xed0801d0 0x4>;
			clocks = <0x2a 0x48 0x15>;
			clock-output-names = "gclk_adc_parent";
			amb,div-width = <0x10>;
			amb,div-shift = <0x0>;
			linux,phandle = <0x49>;
			phandle = <0x49>;
		};

		gclk_adc: gclk-adc {
			#clock-cells = <0x0>;
			compatible = "ambarella,fixed-factor-clock";
			clocks = <0x49>;
			clock-output-names = "gclk_adc";
			clock-mult = <0x1>;
			clock-div = <0x2>;
			linux,phandle = <0x8>;
			phandle = <0x8>;
		};

		gclk_ir: gclk-ir {
			#clock-cells = <0x0>;
			compatible = "ambarella,div-clock";
			reg = <0xed080044 0x4>;
			clocks = <0x2a>;
			clock-output-names = "gclk_ir";
			amb,div-width = <0x18>;
			amb,div-shift = <0x0>;
			linux,phandle = <0x7>;
			phandle = <0x7>;
		};

		gclk_pwm: gclk-pwm {
			#clock-cells = <0x0>;
			compatible = "ambarella,composite-clock";
			reg = <0xed080084 0x4 0xed0801c4 0x4>;
			clocks = <0xb 0x2 0x47 0x2a>;
			clock-output-names = "gclk_pwm";
			assigned-clocks = <0x11>;
			assigned-clock-parents = <0x47>;
			amb,div-width = <0x18>;
			amb,div-shift = <0x0>;
			linux,phandle = <0x11>;
			phandle = <0x11>;
		};

		gclk_ssi: gclk-ssi {
			#clock-cells = <0x0>;
			compatible = "ambarella,div-clock";
			reg = <0xed08003c 0x4>;
			clocks = <0x3>;
			clock-output-names = "gclk_ssi";
			amb,div-width = <0x18>;
			amb,div-shift = <0x0>;
			linux,phandle = <0x4a>;
			phandle = <0x4a>;
		};

		gclk_ssi2: gclk-ssi2 {
			#clock-cells = <0x0>;
			compatible = "ambarella,div-clock";
			reg = <0xed0800ec 0x4>;
			clocks = <0x3>;
			clock-output-names = "gclk_ssi2";
			amb,div-width = <0x18>;
			amb,div-shift = <0x0>;
		};

		gclk_ssi3: gclk-ssi3 {
			#clock-cells = <0x0>;
			compatible = "ambarella,composite-clock";
			reg = <0xed080518 0x4 0xed08051c 0x4>;
			clocks = <0x47 0x3 0x4a 0x2a>;
			clock-output-names = "gclk_ssi3";
			amb,div-width = <0x18>;
			amb,div-shift = <0x0>;
			linux,phandle = <0x17>;
			phandle = <0x17>;
		};
	};

	sub_scheduler: sub_scheduler0 {
		compatible = "ambarella,sub-scheduler";
		interrupts = <0x0 0x99 0x4 0x0 0x9a 0x4 0x0 0x9b 0x4 0x0 0x9c 0x4 0x0 0x9d 0x4>;
		memory-region = <0x4b>;
	};

	uboot_cfg {
		#address-cells = <0x1>;
		#size-cells = <0x0>;
		console = "ttyS0";
		kernel_addr = <0x280000>;
		ram_size = <0x80000000>;
		fb_serial = "Ambarella CV25";
		mtdids = "nand0=amba_nand";
		mtdparts = "amba_nand:128K(bootstrap),1M(bootloader),8M(kernel),128M(rootfs)";
	};

	lcd_md092ml04 {
		compatible = "ambarella,md092ml04";
		pwr-gpios = <0xc 0x7 0x1>;
		backlight-gpios = <0x10 0x2a 0x1>;
	};

	sound {
		compatible = "ambarella,audio-board";
		simple-audio-card,name = "ak4951 @ AMBEVK";
		simple-audio-card,mclk-fs = <0x100>;
		simple-audio-card,widgets = "Speaker", "Speaker", "Headphone", "HP Jack", "Line", "Line In", "Line", "Line Out", "Microphone", "Mic Internal", "Microphone", "Mic External";
		simple-audio-card,routing = "LIN2", "Mic Bias", "RIN2", "Mic Bias", "Mic Bias", "Mic Internal", "LIN3", "Line In", "RIN3", "Line In", "Line Out", "SPKLO", "HP Jack", "HPL", "HP Jack", "HPR", "Speaker", "SPKLO";

		simple-audio-card,dai-link@0 {
			format = "i2s";

			cpu {
				sound-dai = <0x4c>;
			};

			codec {
				sound-dai = <0x4d>;
			};
		};

		simple-audio-card,dai-link@1 {
			format = "i2s";

			cpu {
				sound-dai = <0x4c>;
			};

			codec {
				sound-dai = <0x4e>;
			};
		};
	};
};
